# NVIC_1.0 register map
Vendor: Texas Instruments
Peripheral module from a debugger description file (folder msp).
Registers are 32-bit, read-write, no defined reset value unless marked. A register's access mark holds for its fields unless they carry their own. Offsets are as the file gives them; lines under a group give offsets from that group; [hi:lo] are bit positions; {n}, {i} and the like mark numbered series; 'fields as' and 'values as' point back to an identical list; <NAME> marks a mode.

## NVIC
{0xE000E100+4i} NVIC_NVIC_ISER{i} access not given (i=0..2) — Enables or reads the enabled state of each group of 32 interrupts
{0xE000E180+4i} NVIC_NVIC_ICER{i} access not given (i=0..2) — Clears or reads the enabled state of each group of 32 interrupts
{0xE000E200+4i} NVIC_NVIC_ISPR{i} access not given (i=0..2) — Enables or reads the pending state of each group of 32 interrupts
{0xE000E280+4i} NVIC_NVIC_ICPR{i} access not given (i=0..2) — Clears or reads the pending state of each group of 32 interrupts
{0xE000E300+4i} NVIC_NVIC_IABR{i} access not given (i=0..2) — For each group of 32 interrupts, shows the active state of each interrupt
{0xE000E380+4i} NVIC_NVIC_ITNS{i} access not given (i=0..2) — For each group of 32 interrupts, determines whether each interrupt targets Non-secure or Secure state
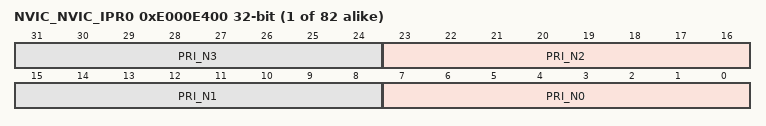
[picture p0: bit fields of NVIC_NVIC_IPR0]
{0xE000E400+4i} NVIC_NVIC_IPR{i} (i=0..81) — Sets or reads interrupt priorities
  [8n+7:8n] PRI_N{n} (n=0..3) — For register NVIC_IPR*{i}, `IAAMO the priority of interrupt number 4*{i}+{n}, or is RES0 if the PE does not implement this interrupt
